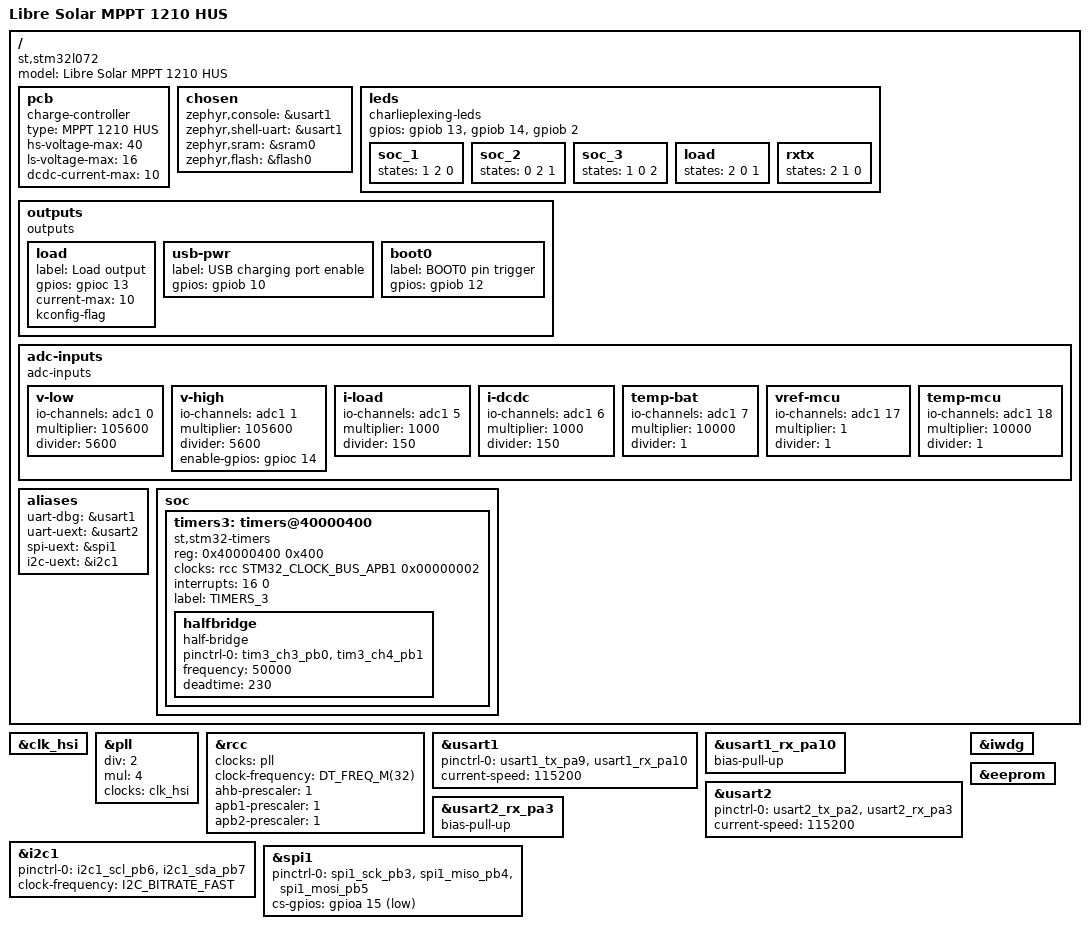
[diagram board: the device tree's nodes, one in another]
/*
 * Copyright (c) The Libre Solar Project Contributors
 *
 * SPDX-License-Identifier: Apache-2.0
 */

/dts-v1/;
#include <st/l0/stm32l072Xz.dtsi>
#include <st/l0/stm32l072r(b-z)tx-pinctrl.dtsi>

/ {
	model = "Libre Solar MPPT 1210 HUS";
	compatible = "st,stm32l072";

	pcb {
		compatible = "charge-controller";

		type = "MPPT 1210 HUS";

		hs-voltage-max = <40>;
		ls-voltage-max = <16>;
		dcdc-current-max = <10>;
	};

	chosen {
		zephyr,console = &usart1;
		zephyr,shell-uart = &usart1;
		zephyr,sram = &sram0;
		zephyr,flash = &flash0;
	};

	leds {
		compatible = "charlieplexing-leds";
		gpios = <&gpiob 13 GPIO_ACTIVE_HIGH>,	/* Pin A */
			<&gpiob 14 GPIO_ACTIVE_HIGH>,	/* Pin B */
			<&gpiob 2 GPIO_ACTIVE_HIGH>;	/* Pin C */

		soc_1 {
			states = <1 2 0>;	/* LED1 */
		};

		soc_2 {
			states = <0 2 1>;	/* LED2 */
		};

		soc_3 {
			states = <1 0 2>;	/* LED3 */
		};

		load {
			states = <2 0 1>;	/* LED4 */
		};

		rxtx {
			states = <2 1 0>;	/* LED5 */
		};
	};

	outputs {
		compatible = "outputs";

		load {
			label = "Load output";
			gpios = <&gpioc 13 GPIO_ACTIVE_HIGH>;
			current-max = <10>;
			kconfig-flag;	/* make node visible in Kconfig */
		};

		usb-pwr {
			label = "USB charging port enable";
			gpios = <&gpiob 10 GPIO_ACTIVE_HIGH>;
		};

		boot0 {
			label = "BOOT0 pin trigger";
			gpios = <&gpiob 12 GPIO_ACTIVE_HIGH>;
		};
	};

	adc-inputs {
		compatible = "adc-inputs";

		v-low {
			io-channels = <&adc1 0>;
			multiplier = <105600>;
			divider = <5600>;
		};

		v-high {
			io-channels = <&adc1 1>;
			multiplier = <105600>;
			divider = <5600>;
			enable-gpios = <&gpioc 14 GPIO_ACTIVE_HIGH>;
		};

		i-load {
			io-channels = <&adc1 5>;
			// amp gain: 50, resistor: 3 mOhm
			multiplier = <1000>;
			divider = <150>;	// 3*50
		};

		i-dcdc {
			io-channels = <&adc1 6>;
			// amp gain: 50, resistor: 3 mOhm
			multiplier = <1000>;
			divider = <150>;	// 3*50
		};

		temp-bat {
			io-channels = <&adc1 7>;
			multiplier = <10000>;
			divider = <1>;
		};

		vref-mcu {
			io-channels = <&adc1 17>;
			multiplier = <1>;
			divider = <1>;
		};

		temp-mcu {
			io-channels = <&adc1 18>;
			multiplier = <10000>;
			divider = <1>;
		};
	};

	aliases {
		uart-dbg = &usart1;
		uart-uext = &usart2;
		spi-uext = &spi1;
		i2c-uext = &i2c1;
	};

	soc {
		// not (yet) provided by Zephyr dts, but necessary for dcdc node
		timers3: timers@40000400 {
			compatible = "st,stm32-timers";
			reg = <0x40000400 0x400>;
			clocks = <&rcc STM32_CLOCK_BUS_APB1 0x00000002>;
			interrupts = <16 0>;
			interrupt-names = "global";
			status = "disabled";
			label = "TIMERS_3";
		};
	};
};

&clk_hsi {
	status = "okay";
};

&pll {
	div = <2>;
	mul = <4>;
	clocks = <&clk_hsi>;
	status = "okay";
};

&rcc {
	clocks = <&pll>;
	clock-frequency = <DT_FREQ_M(32)>;
	ahb-prescaler = <1>;
	apb1-prescaler = <1>;
	apb2-prescaler = <1>;
};

&usart1 {
	pinctrl-0 = <&usart1_tx_pa9 &usart1_rx_pa10>;
	current-speed = <115200>;
	status = "okay";
};

&usart1_rx_pa10 {
	bias-pull-up;	// avoid junk characters if pin is left floating
};

&usart2 {
	pinctrl-0 = <&usart2_tx_pa2 &usart2_rx_pa3>;
	current-speed = <115200>;
	status = "okay";
};

&usart2_rx_pa3 {
	bias-pull-up;	// avoid junk characters if pin is left floating
};

&i2c1 {
	pinctrl-0 = <&i2c1_scl_pb6 &i2c1_sda_pb7>;
	clock-frequency = <I2C_BITRATE_FAST>;
	status = "okay";
};

&spi1 {
	pinctrl-0 = <&spi1_sck_pb3 &spi1_miso_pb4 &spi1_mosi_pb5>;
	cs-gpios = <&gpioa 15 GPIO_ACTIVE_LOW>;
	status = "okay";
};

&iwdg {
	status = "okay";
};

&timers3 {
	status = "okay";

	halfbridge {
		compatible = "half-bridge";
		pinctrl-0 = <&tim3_ch3_pb0 &tim3_ch4_pb1>;
		frequency = <50000>;
		deadtime = <230>;
	};
};

&eeprom {
	status = "okay";
};
